# LPC11E6x register map
File version: 0.8
LPC11E6x ARM cortex-m0+
CPU: CM0PLUS r0p1, little endian, no MPU, no FPU, 0x2 interrupt priority bits, 0x0 interrupts
Registers are 32-bit, read-write, reset 0x0 unless marked. A register's access mark holds for its fields unless they carry their own. Offsets are from the block's base; lines under a group give offsets from that group; [hi:lo] are bit positions; {n}, {i} and the like mark numbered series; 'fields as' and 'values as' point back to an identical list; <NAME> marks a mode.

## Memory map
0x40000000 I2C0 size 0xFFF — I2C-bus controller
0x40004000 WWDT size 0xFFF — Windowed Watchdog Timer (WWDT)
0x40008000 USART0 size 0xFFF
0x4000C000 CT16B0 size 0xFFF — 16-bit counter/timers CT16B0
0x40010000 CT16B1 size 0xFFF — 16-bit counter/timers CT16B1
0x40014000 CT32B0 size 0xFFF — 32-bit counter/timers CT32B0
0x40018000 CT32B1 size 0xFFF — 32-bit counter/timers CT32B1
0x4001C000 ADC size 0xFFF — 12-bit Analog-to-Digital Converter (ADC)
0x40020000 I2C1 size 0xFFF
0x40024000 RTC size 0xFFF — Real-Time Clock (RTC)
0x40028000 DMATRIGMUX size 0xFFF — DMA controller
0x40038000 PMU size 0xFFF — Power Management Unit (PMU)
0x4003C000 FLASHCTRL size 0xFFF — Flash controller
0x40040000 SSP0 size 0xFFF — SSP/SPI
0x40044000 IOCON size 0xFFF — I/O control (IOCON)
0x40048000 SYSCON size 0xFFF — System configuration (SYSCON)
0x4004C000 USART4 size 0xFFF
0x40058000 SSP1 size 0xFFF
0x4005C000 GINT0 size 0xFFF — GPIO group interrupt 0
0x40060000 GINT1 size 0xFFF
0x4006C000 USART1 size 0xFFF
0x40070000 USART2 size 0xFFF
0x40074000 USART3 size 0xFFF
0x50000000 CRC size 0xFFF — Cyclic Redundancy Check (CRC) engine
0x50004000 DMA size 0xFFF — DMA controller
0x5000C000 SCT0 size 0xFFF — State Configurable Timers (SCTimer/PWM)
0x5000E000 SCT1 size 0xFFF
0xA0000000 GPIO_PORT size 0x3FFF — General Purpose I/O (GPIO)
0xA0004000 PINT size 0xFFF — Pin interrupt and pattern match (PINT)

## Interrupts
{n} PIN_INT{n} (PINT) (n=0..7)
8 GINT0
9 GINT1
10 I2C1
11 USART1_4 (USART4, USART1, USART3)
12 USART2_3 (USART2)
13 SCT0_1 (SCT0, SCT1)
14 SSP1
15 I2C0
16 CT16B0
17 CT16B1
18 CT32B0
19 CT32B1
20 SSP0
21 USART (USART0)
24 ADC_A (ADC)
25 RTC
26 BOD_WDT (SYSCON)
27 FLASH (FLASHCTRL)
28 DMA

## WWDT — Windowed Watchdog Timer (WWDT)
Base 0x40004000
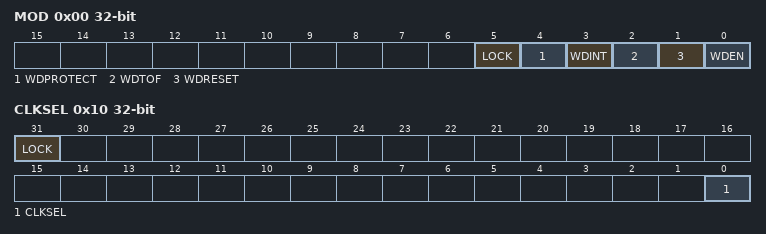
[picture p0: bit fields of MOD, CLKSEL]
0x00 MOD — Watchdog mode register. This register contains the basic mode and status of the Watchdog Timer.
  [5] LOCK — A 1 in this bit prevents disabling or powering down the clock source selected by bit 0 of the WDCLKSRC register and also prevents switching to a clock source that is disabled or powered down. This bit can be set once by software and is only cleared by any reset. If this bit is one and the WWDT clock source is the IRC when Deep-sleep or Power-down modes are entered, the IRC remains running thereby increasing power consumption in Deep-sleep mode and potentially preventing the part of entering Power-down mode correctly (see Section 15.7).
  [4] WDPROTECT — Watchdog update mode. This bit can be set once by software and is only cleared by a reset.
    0=NOT_LOCKED (The watchdog time-out value (TC) can be changed at any time.); 1=LOCKED (The watchdog time-out value (TC) can be changed only after the counter is below the value of WDWARNINT and WDWINDOW.)
  [3] WDINT — Warning interrupt flag. Set when the timer reaches the value in WDWARNINT. Cleared by software.
  [2] WDTOF — Watchdog time-out flag. Set when the watchdog timer times out, by a feed error, or by events associated with WDPROTECT. Cleared by software. Causes a chip reset if WDRESET = 1.
  [1] WDRESET — Watchdog reset enable bit. Once this bit has been written with a 1 it cannot be rewritten with a 0.
    0=INTERRUPT (A watchdog timeout will not cause a chip reset.)
  [0] WDEN — Watchdog enable bit. Once this bit has been written with a 1 it cannot be rewritten with a 0.
    0=STOPPED (The watchdog timer is stopped.); 1=RUNNING (The watchdog timer is running.)
0x04 TC reset 0xFF — Watchdog timer constant register. This 24-bit register determines the time-out value.
  [23:0] COUNT — Watchdog time-out value.
0x08 FEED wo reset not defined — Watchdog feed sequence register. Writing 0xAA followed by 0x55 to this register reloads the Watchdog timer with the value contained in WDTC.
  [7:0] FEED — Feed value should be 0xAA followed by 0x55.
0x0C TV ro reset 0xFF — Watchdog timer value register. This 24-bit register reads out the current value of the Watchdog timer.
  [23:0] COUNT — Counter timer value.
0x10 CLKSEL — Watchdog clock select register.
  [31] LOCK — If this bit is set to one writing to this register does not affect bit 0. The clock source can only be changed by first clearing this bit, then writing the new value of bit 0.
  [0] CLKSEL — Selects source of WDT clock
    0=IRC; 1=WATCHDOG_OSCILLATOR_ (Watchdog oscillator (WDOSC))
0x14 WARNINT — Watchdog Warning Interrupt compare value.
  [9:0] WARNINT — Watchdog warning interrupt compare value.
0x18 WINDOW reset 0xFFFFFF — Watchdog Window compare value.
  [23:0] WINDOW — Watchdog window value.
